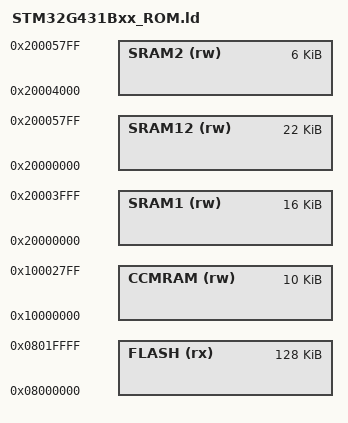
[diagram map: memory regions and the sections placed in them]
/* STM32G431Bxx — Cat2, 128K flash, Access line — run from ROM.
   Generated by narray from MEMORY.periph, DO NOT EDIT. */

MEMORY
{
  FLASH  (rx) : ORIGIN = 0x8000000, LENGTH = 128K
  CCMRAM (rw) : ORIGIN = 0x10000000, LENGTH = 10K  /* aliased at 0x20005800 */
  SRAM1  (rw) : ORIGIN = 0x20000000, LENGTH = 16K
  SRAM2  (rw) : ORIGIN = 0x20004000, LENGTH = 6K
  SRAM12 (rw) : ORIGIN = 0x20000000, LENGTH = 22K  /* SRAM1+SRAM2, contiguous */
}

REGION_ALIAS("TEXT", FLASH);  /* code & vectors in flash           */
REGION_ALIAS("DATA", SRAM1);  /* .data/.bss run in SRAM            */
REGION_ALIAS("LOAD", FLASH);  /* .data initialiser image in flash */
REGION_ALIAS("FAST", FLASH);  /* NARRAY_FAST code home            */
REGION_ALIAS("DMARAM", SRAM1);  /* NARRAY_DMABUF buffers */
REGION_ALIAS("SCRATCH", CCMRAM);  /* stack + crash record  */

_estack = ORIGIN(CCMRAM) + LENGTH(CCMRAM); /* top of stack */

INCLUDE devs.ld      /* peripheral addresses (narray) */
INCLUDE sections.ld /* section layout (lib)          */
